# LPC844 register map
Vendor: nxp.com; File version: 1.0
CPU: CM0PLUS r0p0, little endian, no MPU, no FPU, VTOR, 2 interrupt priority bits
Registers are 32-bit, read-write, reset 0x0 unless marked. A register's access mark holds for its fields unless they carry their own. Offsets are from the block's base; [hi:lo] are bit positions; {n}, {i} and the like mark numbered series; 'fields as' and 'values as' point back to an identical list.

## IOCON — LPC84x I/O pin configuration (IOCON)
Base 0x40044000
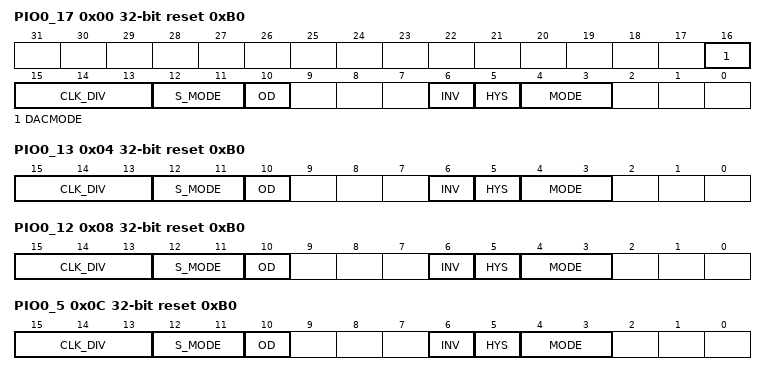
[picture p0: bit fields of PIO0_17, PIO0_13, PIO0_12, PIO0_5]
0x00 PIO0_17 reset 0xB0 — Digital I/O control for pins PIO0_17
  [16] DACMODE — DAC mode enable.
    0=DISABLE; 1=ENABLE
  [15:13] CLK_DIV — Select peripheral clock divider for input filter sampling clock. Value 0x7 is reserved.
    {v}=IOCONCLKDIV{v} (v=0..6)
  [12:11] S_MODE — Digital filter sample mode.
    0=Bypass input filter; 1=1 clock cycle. Input pulses shorter than one filter clock are rejected.; 2=2 clock cycles. Input pulses shorter than two filter clocks are rejected.; 3=3 clock cycles. Input pulses shorter than three filter clocks are rejected.
  [10] OD — Open-drain mode.
    0=DISABLE; 1=ENABLED (Open-drain mode enabled. Remark: This is not a true open-drain mode.)
  [6] INV — Invert input
    0=NOT_INVERTED (Input not inverted (HIGH on pin reads as 1; LOW on pin reads as 0).); 1=INVERTED (Input inverted (HIGH on pin reads as 0, LOW on pin reads as 1).)
  [5] HYS — Hysteresis.
    0=DISABLE; 1=ENABLE
  [4:3] MODE — Selects function mode (on-chip pull-up/pull-down resistor control).
    0=INACTIVE (Inactive. Inactive (no pull-down/pull-up resistor enabled).); 1=PULL_DOWN (Pull-down. Pull-down resistor enabled.); 2=PULL_UP (Pull-up. Pull-up resistor enabled.); 3=REPEATER (Repeater. Repeater mode.)
0x04 PIO0_13 reset 0xB0 — Digital I/O control for pins PIO0_13
  [15:13] CLK_DIV — Select peripheral clock divider for input filter sampling clock. Value 0x7 is reserved.
    {v}=IOCONCLKDIV{v} (v=0..6)
  [12:11] S_MODE — Digital filter sample mode.
    values as PIO0_17.S_MODE
  [10] OD — Open-drain mode.
    values as PIO0_17.OD
  [6] INV — Invert input
    values as PIO0_17.INV
  [5] HYS — Hysteresis.
    0=DISABLE; 1=ENABLE
  [4:3] MODE — Selects function mode (on-chip pull-up/pull-down resistor control).
    values as PIO0_17.MODE
0x08 PIO0_12 reset 0xB0 — Digital I/O control for pins PIO0_12
  fields as PIO0_13
0x0C PIO0_5 reset 0xB0 — Digital I/O control for pins PIO0_5
  fields as PIO0_13
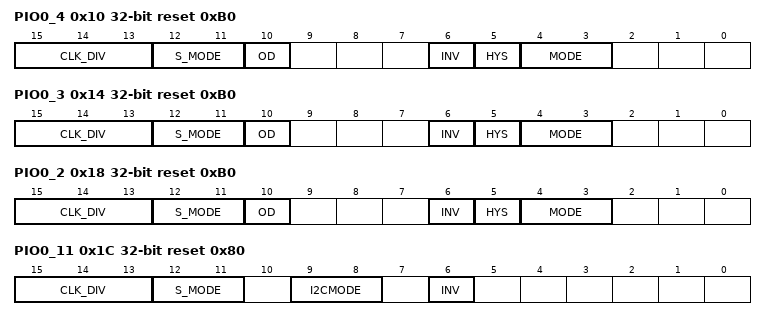
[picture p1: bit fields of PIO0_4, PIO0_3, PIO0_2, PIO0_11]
0x10 PIO0_4 reset 0xB0 — Digital I/O control for pins PIO0_4
  fields as PIO0_13
0x14 PIO0_3 reset 0xB0 — Digital I/O control for pins PIO0_3
  fields as PIO0_13
0x18 PIO0_2 reset 0xB0 — Digital I/O control for pins PIO0_2
  fields as PIO0_13
0x1C PIO0_11 reset 0x80 — Digital I/O control for pins PIO0_11
  [15:13] CLK_DIV — Select peripheral clock divider for input filter sampling clock. Value 0x7 is reserved.
    {v}=IOCONCLKDIV{v} (v=0..6)
  [12:11] S_MODE — Digital filter sample mode.
    values as PIO0_17.S_MODE
  [9:8] I2CMODE — Selects I2C mode.
    0=STANDARAD_I2C (Standard mode/ Fast-mode I2C.); 1=Standard GPIO functionality. Requires external pull-up for GPIO output function.; 2=FAST_PLUS_I2C (Fast-mode Plus I2C)
  [6] INV — Invert input
    values as PIO0_17.INV
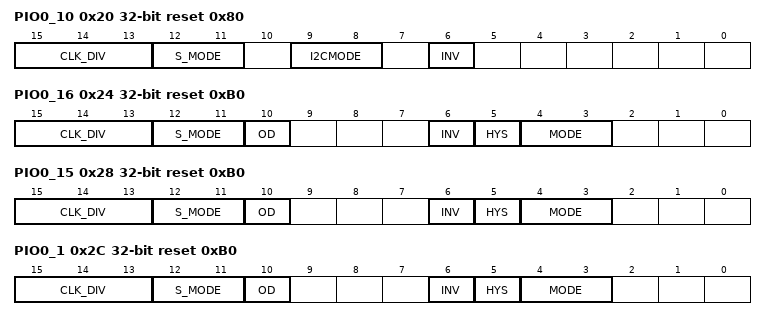
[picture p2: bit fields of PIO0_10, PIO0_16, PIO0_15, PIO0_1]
0x20 PIO0_10 reset 0x80 — Digital I/O control for pins PIO0_10
  fields as PIO0_11
0x24 PIO0_16 reset 0xB0 — Digital I/O control for pins PIO0_16
  fields as PIO0_13
0x28 PIO0_15 reset 0xB0 — Digital I/O control for pins PIO0_15
  fields as PIO0_13
0x2C PIO0_1 reset 0xB0 — Digital I/O control for pins PIO0_1
  fields as PIO0_13
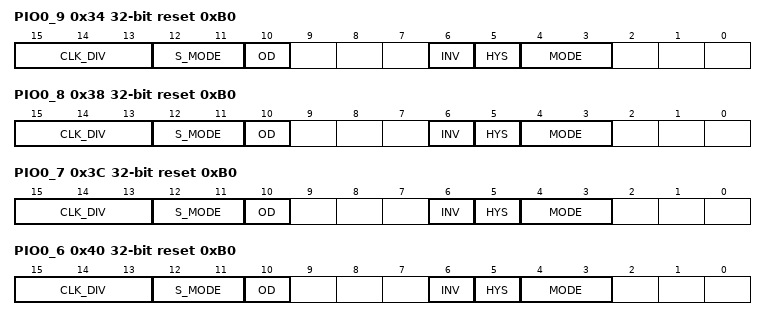
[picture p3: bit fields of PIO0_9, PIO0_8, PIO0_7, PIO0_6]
0x34 PIO0_9 reset 0xB0 — Digital I/O control for pins PIO0_9
  fields as PIO0_13
0x38 PIO0_8 reset 0xB0 — Digital I/O control for pins PIO0_8
  fields as PIO0_13
0x3C PIO0_7 reset 0xB0 — Digital I/O control for pins PIO0_7
  fields as PIO0_13
0x40 PIO0_6 reset 0xB0 — Digital I/O control for pins PIO0_6
  fields as PIO0_13
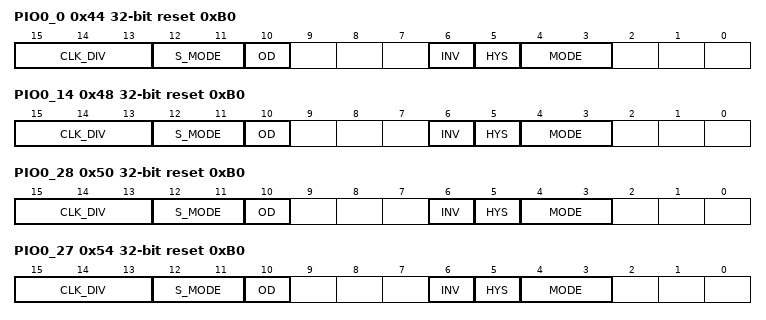
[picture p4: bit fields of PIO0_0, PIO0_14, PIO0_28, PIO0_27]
0x44 PIO0_0 reset 0xB0 — Digital I/O control for pins PIO0_0
  fields as PIO0_13
0x48 PIO0_14 reset 0xB0 — Digital I/O control for pins PIO0_14
  fields as PIO0_13
0x50 PIO0_28 reset 0xB0 — Digital I/O control for pins PIO0_28
  fields as PIO0_13
0x54 PIO0_27 reset 0xB0 — Digital I/O control for pins PIO0_27
  fields as PIO0_13
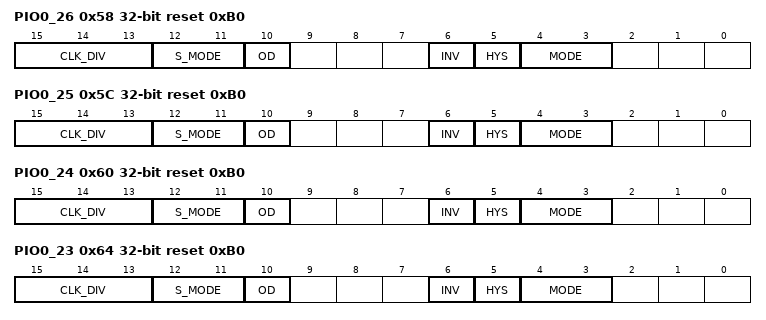
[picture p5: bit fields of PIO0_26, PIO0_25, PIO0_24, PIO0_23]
0x58 PIO0_26 reset 0xB0 — Digital I/O control for pins PIO0_26
  fields as PIO0_13
0x5C PIO0_25 reset 0xB0 — Digital I/O control for pins PIO0_25
  fields as PIO0_13
0x60 PIO0_24 reset 0xB0 — Digital I/O control for pins PIO0_24
  fields as PIO0_13
0x64 PIO0_23 reset 0xB0 — Digital I/O control for pins PIO0_23
  fields as PIO0_13
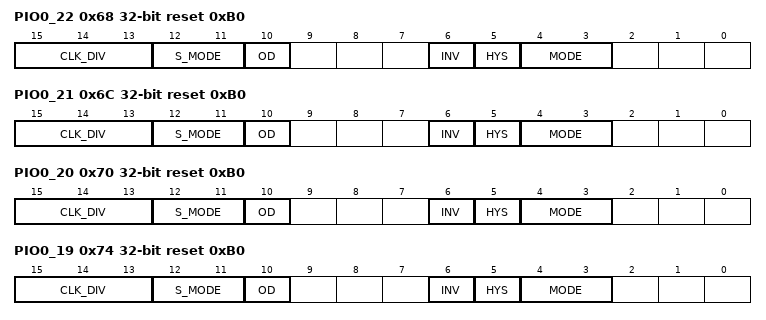
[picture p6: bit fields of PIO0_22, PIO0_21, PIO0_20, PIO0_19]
0x68 PIO0_22 reset 0xB0 — Digital I/O control for pins PIO0_22
  fields as PIO0_13
0x6C PIO0_21 reset 0xB0 — Digital I/O control for pins PIO0_21
  fields as PIO0_13
0x70 PIO0_20 reset 0xB0 — Digital I/O control for pins PIO0_20
  fields as PIO0_13
0x74 PIO0_19 reset 0xB0 — Digital I/O control for pins PIO0_19
  fields as PIO0_13
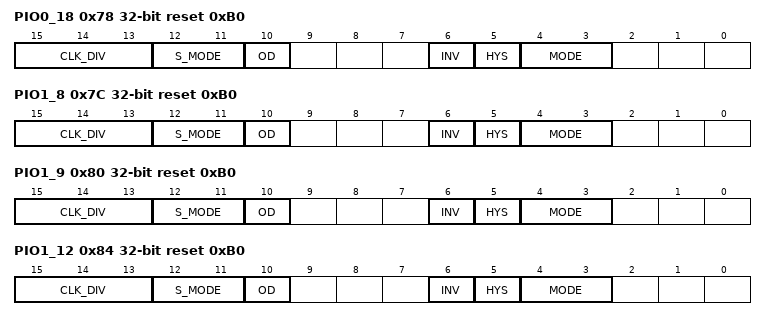
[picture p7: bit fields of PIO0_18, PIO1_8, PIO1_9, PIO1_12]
0x78 PIO0_18 reset 0xB0 — Digital I/O control for pins PIO0_18
  fields as PIO0_13
0x7C PIO1_8 reset 0xB0 — Digital I/O control for pins PIO1_8
  fields as PIO0_13
0x80 PIO1_9 reset 0xB0 — Digital I/O control for pins PIO1_9
  fields as PIO0_13
0x84 PIO1_12 reset 0xB0 — Digital I/O control for pins PIO1_12
  fields as PIO0_13
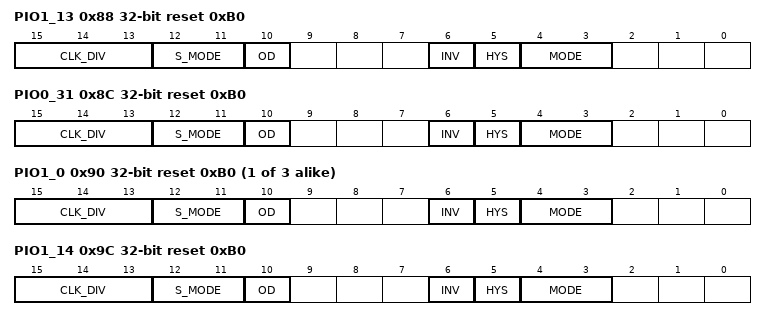
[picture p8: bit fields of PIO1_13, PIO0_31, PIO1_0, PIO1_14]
0x88 PIO1_13 reset 0xB0 — Digital I/O control for pins PIO1_13
  fields as PIO0_13
0x8C PIO0_31 reset 0xB0 — Digital I/O control for pins PIO0_31
  fields as PIO0_13
{0x90+4i} PIO1_{i} reset 0xB0 (i=0..2) — Digital I/O control for pins PIO1_{i}
  fields as PIO0_13
0x9C PIO1_14 reset 0xB0 — Digital I/O control for pins PIO1_14
  fields as PIO0_13
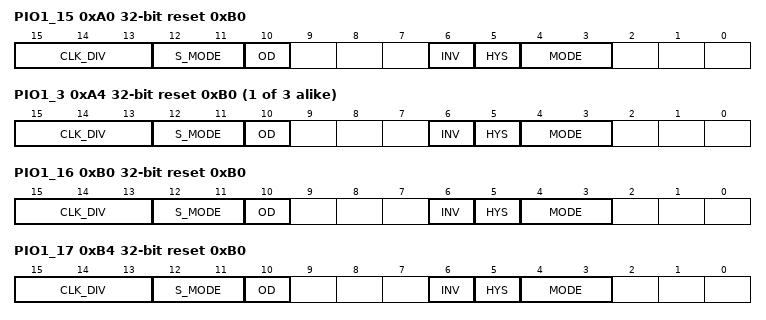
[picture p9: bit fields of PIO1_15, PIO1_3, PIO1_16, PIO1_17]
0xA0 PIO1_15 reset 0xB0 — Digital I/O control for pins PIO1_15
  fields as PIO0_13
{0x98+4i} PIO1_{i} reset 0xB0 (i=3..5) — Digital I/O control for pins PIO1_{i}
  fields as PIO0_13
0xB0 PIO1_16 reset 0xB0 — Digital I/O control for pins PIO1_16
  fields as PIO0_13
0xB4 PIO1_17 reset 0xB0 — Digital I/O control for pins PIO1_17
  fields as PIO0_13
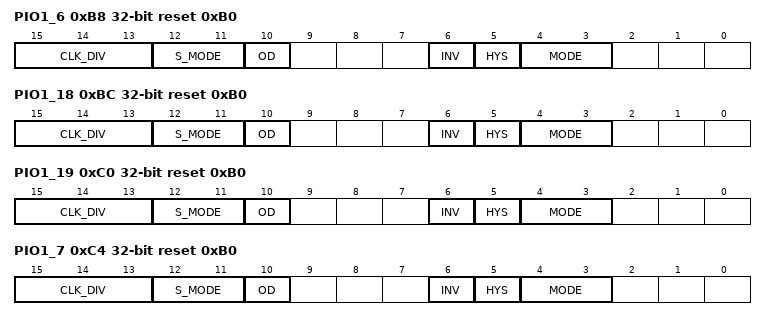
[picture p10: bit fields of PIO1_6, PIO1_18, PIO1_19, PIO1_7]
0xB8 PIO1_6 reset 0xB0 — Digital I/O control for pins PIO1_6
  fields as PIO0_13
0xBC PIO1_18 reset 0xB0 — Digital I/O control for pins PIO1_18
  fields as PIO0_13
0xC0 PIO1_19 reset 0xB0 — Digital I/O control for pins PIO1_19
  fields as PIO0_13
0xC4 PIO1_7 reset 0xB0 — Digital I/O control for pins PIO1_7
  fields as PIO0_13
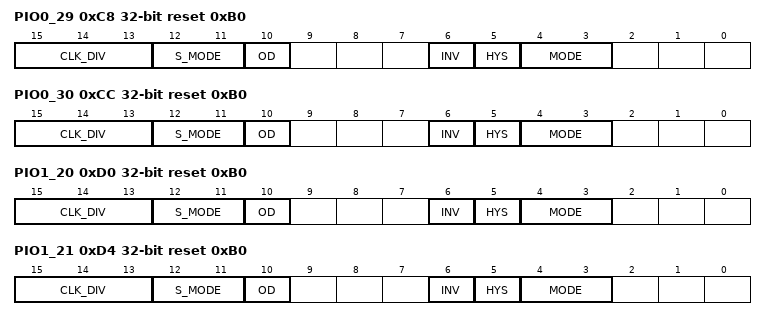
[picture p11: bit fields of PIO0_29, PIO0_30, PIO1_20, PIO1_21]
0xC8 PIO0_29 reset 0xB0 — Digital I/O control for pins PIO0_29
  fields as PIO0_13
0xCC PIO0_30 reset 0xB0 — Digital I/O control for pins PIO0_30
  fields as PIO0_13
0xD0 PIO1_20 reset 0xB0 — Digital I/O control for pins PIO1_20
  fields as PIO0_13
0xD4 PIO1_21 reset 0xB0 — Digital I/O control for pins PIO1_21
  fields as PIO0_13
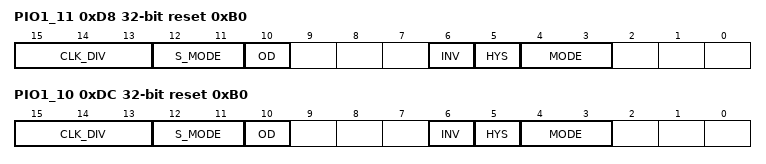
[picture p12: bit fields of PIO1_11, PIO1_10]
0xD8 PIO1_11 reset 0xB0 — Digital I/O control for pins PIO1_11
  fields as PIO0_13
0xDC PIO1_10 reset 0xB0 — Digital I/O control for pins PIO1_10
  fields as PIO0_13

## Notices in the file
Copyright 2016-2019 NXP
All rights reserved.
SPDX-License-Identifier: BSD-3-Clause
